# SYSTICK register map
Vendor: Texas Instruments
Peripheral module from a debugger description file (folder UCD3138R064RJA).
Registers are 32-bit, access per field, reset 0x0 unless marked. A register's access mark holds for its fields unless they carry their own. Offsets are as the file gives them; lines under a group give offsets from that group; [hi:lo] are bit positions; {n}, {i} and the like mark numbered series; 'fields as' and 'values as' point back to an identical list; <NAME> marks a mode.

## SYSTICK
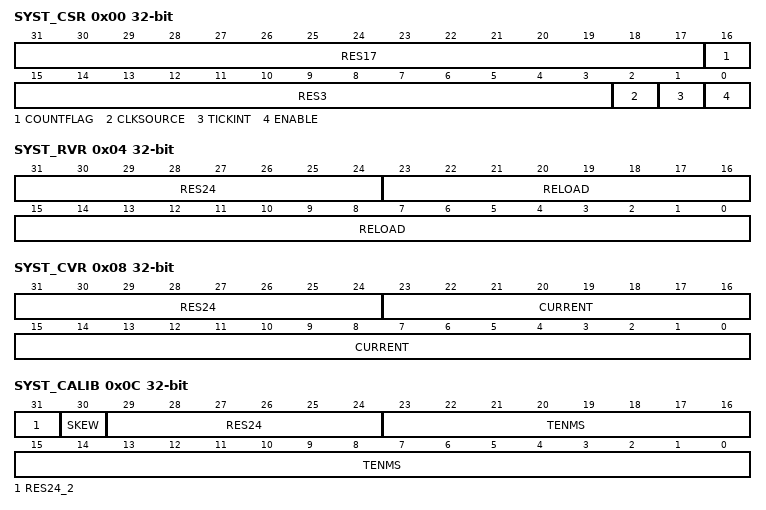
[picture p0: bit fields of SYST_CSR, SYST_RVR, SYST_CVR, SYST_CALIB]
0x00 SYST_CSR — Controls and provides status date for the SysTick timer
  [31:17] RES17 ro — Software should not rely on the value of a reserved. Writing any other value than the reset value may result in undefined behavior.
  [16] COUNTFLAG rw — Indicates whether the counter has counted to zero since the last read of this register
  [15:3] RES3 ro — Software should not rely on the value of a reserved. Writing any other value than the reset value may result in undefined behavior.
  [2] CLKSOURCE rw — Indicates the SysTick clock source
  [1] TICKINT rw — Indicates whether counting to 0 causes the status of the SysTick exception to change to pending
  [0] ENABLE rw — Indicates the enabled status of the SysTick counter
0x04 SYST_RVR — Specifies the SysTick timer counter reload value
  [31:24] RES24 ro — Software should not rely on the value of a reserved. Writing any other value than the reset value may result in undefined behavior.
  [23:0] RELOAD rw — Value to load into the SYST_CVR when the counter is enabled and when it reaches 0
0x08 SYST_CVR — Contains the current value of the SysTick counter
  [31:24] RES24 ro — Software should not rely on the value of a reserved. Writing any other value than the reset value may result in undefined behavior.
  [23:0] CURRENT wo — Reads the current value of the SysTick counter. A write of any value clears the field to 0, and also clears the SYST_CSR.COUNTFLAG bit to 0.
0x0C SYST_CALIB ro — Indicates the SysTick calibration value and parameters for the selected security state
  [31] RES24_2 — Software should not rely on the value of a reserved. Writing any other value than the reset value may result in undefined behavior.
  [30] SKEW — Indicates whether the TENMS value is exact
  [29:24] RES24 — Software should not rely on the value of a reserved. Writing any other value than the reset value may result in undefined behavior.
  [23:0] TENMS — Reload value for 10ms (100Hz) timing, subject to system clock skew errors. If the value reads as zero, the calibration value is not known.
